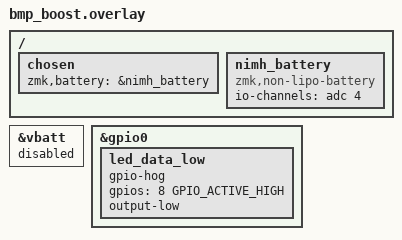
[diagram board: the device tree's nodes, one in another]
/*
 * SPDX-License-Identifier: MIT
 *
 * BMP Boost with two NiMH AAA cells in series per half. ZMK's voltage-divider battery driver, which the
 * bmp_boost board uses, assumes a lithium cell (0% at 3.45 V and below), so a NiMH cell always
 * reads 0%. Use sekigon-gonnoc's non-LiPo battery module instead (pulled in by the board): it
 * reports a NiMH percentage and switches the half off before the cell is over-discharged.
 *
 * The module uses the voltage at the pin as-is, and the BMP Boost's 1:3 divider puts that at a
 * third of the BT input voltage, so bmp_boost.conf gives the module its thresholds divided by three.
 */

/ {
    chosen {
        zmk,battery = &nimh_battery;
    };

    nimh_battery: nimh_battery {
        compatible = "zmk,non-lipo-battery";
        io-channels = <&adc 4>; // the BMP Boost's BT input
    };
};

&vbatt {
    status = "disabled";
};

/*
 * Hold the LEDs' data line (Pro Micro D3, P0.08 on the BMP Boost) low. Nothing drives the LEDs, so
 * the line would float, and the LEDs get just enough from VCC (about 2.2 V) to latch noise on it as
 * a colour (red is all they can show at that voltage) and keep it lit, draining the cells.
 */
&gpio0 {
    led_data_low {
        gpio-hog;
        gpios = <8 GPIO_ACTIVE_HIGH>;
        output-low;
    };
};
